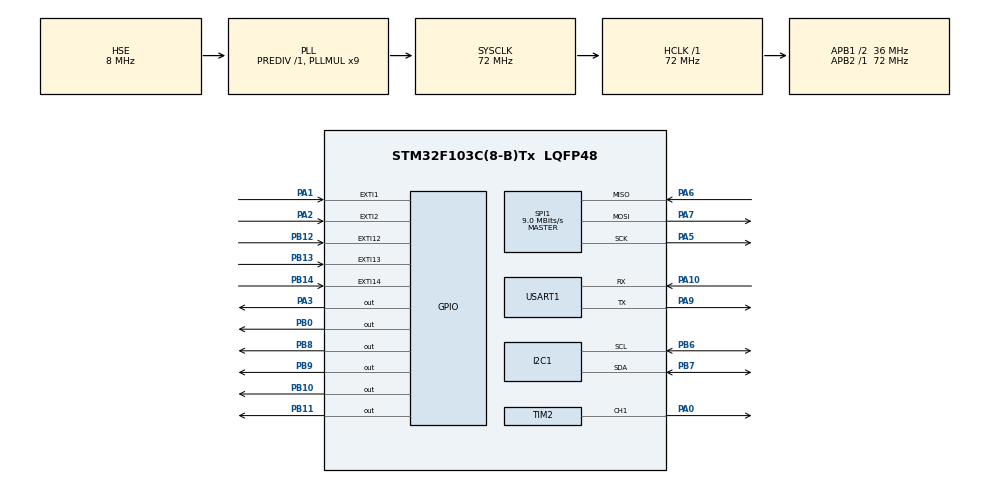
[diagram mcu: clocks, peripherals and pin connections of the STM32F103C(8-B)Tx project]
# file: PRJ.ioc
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I2C1.I2C_Mode=I2C_Standard
Mcu.Family=STM32F1
Mcu.Name=STM32F103C(8-B)Tx
Mcu.Package=LQFP48
NVIC.EXTI15_10_IRQn=true\:1\:0\:true\:false\:true\:true\:true\:true
NVIC.EXTI1_IRQn=true\:1\:0\:true\:false\:true\:true\:true\:true
NVIC.EXTI2_IRQn=true\:1\:0\:true\:false\:true\:true\:true\:true
NVIC.PriorityGroup=NVIC_PRIORITYGROUP_4
NVIC.TIM2_IRQn=true\:2\:0\:true\:false\:true\:true\:true\:true
NVIC.USART1_IRQn=true\:3\:0\:true\:false\:true\:true\:true\:true
PA0-WKUP.Signal=S_TIM2_CH1_ETR
PA1.GPIO_PuPd=GPIO_PULLUP
PA1.Signal=GPXTI1
PA10.Mode=Asynchronous
PA10.Signal=USART1_RX
PA13.Mode=Serial_Wire
PA13.Signal=SYS_JTMS-SWDIO
PA14.Mode=Serial_Wire
PA14.Signal=SYS_JTCK-SWCLK
PA2.GPIO_PuPd=GPIO_PULLUP
PA2.Signal=GPXTI2
PA3.Signal=GPIO_Output
PA5.Mode=Full_Duplex_Master
PA5.Signal=SPI1_SCK
PA6.Mode=Full_Duplex_Master
PA6.Signal=SPI1_MISO
PA7.Mode=Full_Duplex_Master
PA7.Signal=SPI1_MOSI
PA9.Mode=Asynchronous
PA9.Signal=USART1_TX
PB0.Signal=GPIO_Output
PB10.Signal=GPIO_Output
PB11.Signal=GPIO_Output
PB12.Signal=GPXTI12
PB13.GPIO_ModeDefaultEXTI=GPIO_MODE_IT_RISING
PB13.GPIO_PuPd=GPIO_PULLUP
PB13.Signal=GPXTI13
PB14.GPIO_ModeDefaultEXTI=GPIO_MODE_IT_RISING
PB14.GPIO_PuPd=GPIO_PULLUP
PB14.Signal=GPXTI14
PB6.Mode=I2C
PB6.Signal=I2C1_SCL
PB7.Mode=I2C
PB7.Signal=I2C1_SDA
PB8.Signal=GPIO_Output
PB9.Signal=GPIO_Output
PD0-OSC_IN.Mode=HSE-External-Oscillator
PD0-OSC_IN.Signal=RCC_OSC_IN
PD1-OSC_OUT.Mode=HSE-External-Oscillator
PD1-OSC_OUT.Signal=RCC_OSC_OUT
ProjectManager.HeapSize=0x200
ProjectManager.StackSize=0x400
ProjectManager.TargetToolchain=CMake
RCC.AHBFreq_Value=72000000
RCC.APB1CLKDivider=RCC_HCLK_DIV2
RCC.APB1Freq_Value=36000000
RCC.APB1TimFreq_Value=72000000
RCC.APB2Freq_Value=72000000
RCC.APB2TimFreq_Value=72000000
RCC.HCLKFreq_Value=72000000
RCC.PLLMUL=RCC_PLL_MUL9
RCC.PLLSourceVirtual=RCC_PLLSOURCE_HSE
RCC.SYSCLKFreq_VALUE=72000000
RCC.SYSCLKSource=RCC_SYSCLKSOURCE_PLLCLK
RCC.USBFreq_Value=72000000
SH.S_TIM2_CH1_ETR.0=TIM2_CH1,PWM Generation1 CH1
SPI1.BaudRatePrescaler=SPI_BAUDRATEPRESCALER_8
SPI1.CalculateBaudRate=9.0 MBits/s
SPI1.Direction=SPI_DIRECTION_2LINES
SPI1.Mode=SPI_MODE_MASTER
SPI1.VirtualType=VM_MASTER
TIM2.Channel-PWM\ Generation1\ CH1=TIM_CHANNEL_1
TIM2.Period=19999
TIM2.Prescaler=71
USART1.VirtualMode=VM_ASYNC
VP_TIM2_VS_ClockSourceINT.Mode=Internal
board=custom

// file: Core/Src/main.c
/* USER CODE BEGIN Header */
/**
  ******************************************************************************
  * @file           : main.c
  * @brief          : Main program body
  ******************************************************************************
  * @attention
  *
  * Copyright (c) 2026 STMicroelectronics.
  * All rights reserved.
  *
  * This software is licensed under terms that can be found in the LICENSE file
  * in the root directory of this software component.
  * If no LICENSE file comes with this software, it is provided AS-IS.
  *
  ******************************************************************************
  */
/* USER CODE END Header */
#include "main.h"

/* USER CODE BEGIN Includes */
#include "App.h"
/* USER CODE END Includes */

I2C_HandleTypeDef hi2c1;

SPI_HandleTypeDef hspi1;

TIM_HandleTypeDef htim2;

UART_HandleTypeDef huart1;

/* USER CODE BEGIN PV */
Servo_t servo = {&htim2, TIM_CHANNEL_1};
Buzzer_t buzzer = {GPIOA, GPIO_PIN_3};

Keypad_t keypad = {
    // Cot (Columns) - PB12, PB13, PB14: input pull-up, EXTI falling
    .Col1_Port = GPIOB, .Col2_Port = GPIOB, .Col3_Port = GPIOB,
    .Col1_Pin  = GPIO_PIN_12, .Col2_Pin = GPIO_PIN_13, .Col3_Pin = GPIO_PIN_14,
    .Col1_IRQn = EXTI15_10_IRQn, .Col2_IRQn = EXTI15_10_IRQn, .Col3_IRQn = EXTI15_10_IRQn,
    // Hang (Rows) - PB8, PB9, PB10, PB11: output push-pull
    .Row1_Port = GPIOB, .Row2_Port = GPIOB, .Row3_Port = GPIOB, .Row4_Port = GPIOB,
    .Row1_Pin  = GPIO_PIN_8, .Row2_Pin = GPIO_PIN_9, .Row3_Pin = GPIO_PIN_10, .Row4_Pin = GPIO_PIN_11,
};

/* USER CODE END PV */

void SystemClock_Config(void);
static void MX_GPIO_Init(void);
static void MX_I2C1_Init(void);
static void MX_SPI1_Init(void);
static void MX_TIM2_Init(void);
static void MX_USART1_UART_Init(void);

int main(void)
{

  /* MCU Configuration--------------------------------------------------------*/

  /* Reset of all peripherals, Initializes the Flash interface and the Systick. */
  HAL_Init();

  /* Configure the system clock */
  SystemClock_Config();

  /* Initialize all configured peripherals */
  MX_GPIO_Init();
  MX_I2C1_Init();
  MX_SPI1_Init();
  MX_TIM2_Init();
  MX_USART1_UART_Init();
  /* USER CODE BEGIN 2 */
  HAL_Delay(100);
  Flash_Load_Cards();
  App_Init(&keypad ,&buzzer, &huart1, &hi2c1, &hspi1, &servo);

  /* USER CODE END 2 */

  /* Infinite loop */
  /* USER CODE BEGIN WHILE */
  while (1)
  {
    App_Run();

    /* USER CODE END WHILE */

  }
}

void SystemClock_Config(void)
{
  RCC_OscInitTypeDef RCC_OscInitStruct = {0};
  RCC_ClkInitTypeDef RCC_ClkInitStruct = {0};

  /** Initializes the RCC Oscillators according to the specified parameters
  * in the RCC_OscInitTypeDef structure.
  */
  RCC_OscInitStruct.OscillatorType = RCC_OSCILLATORTYPE_HSE;
  RCC_OscInitStruct.HSEState = RCC_HSE_ON;
  RCC_OscInitStruct.HSEPredivValue = RCC_HSE_PREDIV_DIV1;
  RCC_OscInitStruct.HSIState = RCC_HSI_ON;
  RCC_OscInitStruct.PLL.PLLState = RCC_PLL_ON;
  RCC_OscInitStruct.PLL.PLLSource = RCC_PLLSOURCE_HSE;
  RCC_OscInitStruct.PLL.PLLMUL = RCC_PLL_MUL9;
  if (HAL_RCC_OscConfig(&RCC_OscInitStruct) != HAL_OK)
  {
    Error_Handler();
  }

  /** Initializes the CPU, AHB and APB buses clocks
  */
  RCC_ClkInitStruct.ClockType = RCC_CLOCKTYPE_HCLK|RCC_CLOCKTYPE_SYSCLK
                              |RCC_CLOCKTYPE_PCLK1|RCC_CLOCKTYPE_PCLK2;
  RCC_ClkInitStruct.SYSCLKSource = RCC_SYSCLKSOURCE_PLLCLK;
  RCC_ClkInitStruct.AHBCLKDivider = RCC_SYSCLK_DIV1;
  RCC_ClkInitStruct.APB1CLKDivider = RCC_HCLK_DIV2;
  RCC_ClkInitStruct.APB2CLKDivider = RCC_HCLK_DIV1;

  if (HAL_RCC_ClockConfig(&RCC_ClkInitStruct, FLASH_LATENCY_2) != HAL_OK)
  {
    Error_Handler();
  }
}

static void MX_I2C1_Init(void)
{

  hi2c1.Instance = I2C1;
  hi2c1.Init.ClockSpeed = 100000;
  hi2c1.Init.DutyCycle = I2C_DUTYCYCLE_2;
  hi2c1.Init.OwnAddress1 = 0;
  hi2c1.Init.AddressingMode = I2C_ADDRESSINGMODE_7BIT;
  hi2c1.Init.DualAddressMode = I2C_DUALADDRESS_DISABLE;
  hi2c1.Init.OwnAddress2 = 0;
  hi2c1.Init.GeneralCallMode = I2C_GENERALCALL_DISABLE;
  hi2c1.Init.NoStretchMode = I2C_NOSTRETCH_DISABLE;
  if (HAL_I2C_Init(&hi2c1) != HAL_OK)
  {
    Error_Handler();
  }

}

static void MX_SPI1_Init(void)
{

  /* SPI1 parameter configuration*/
  hspi1.Instance = SPI1;
  hspi1.Init.Mode = SPI_MODE_MASTER;
  hspi1.Init.Direction = SPI_DIRECTION_2LINES;
  hspi1.Init.DataSize = SPI_DATASIZE_8BIT;
  hspi1.Init.CLKPolarity = SPI_POLARITY_LOW;
  hspi1.Init.CLKPhase = SPI_PHASE_1EDGE;
  hspi1.Init.NSS = SPI_NSS_SOFT;
  hspi1.Init.BaudRatePrescaler = SPI_BAUDRATEPRESCALER_8;
  hspi1.Init.FirstBit = SPI_FIRSTBIT_MSB;
  hspi1.Init.TIMode = SPI_TIMODE_DISABLE;
  hspi1.Init.CRCCalculation = SPI_CRCCALCULATION_DISABLE;
  hspi1.Init.CRCPolynomial = 10;
  if (HAL_SPI_Init(&hspi1) != HAL_OK)
  {
    Error_Handler();
  }

}

static void MX_TIM2_Init(void)
{

  TIM_ClockConfigTypeDef sClockSourceConfig = {0};
  TIM_MasterConfigTypeDef sMasterConfig = {0};
  TIM_OC_InitTypeDef sConfigOC = {0};

  htim2.Instance = TIM2;
  htim2.Init.Prescaler = 71;
  htim2.Init.CounterMode = TIM_COUNTERMODE_UP;
  htim2.Init.Period = 19999;
  htim2.Init.ClockDivision = TIM_CLOCKDIVISION_DIV1;
  htim2.Init.AutoReloadPreload = TIM_AUTORELOAD_PRELOAD_DISABLE;
  if (HAL_TIM_Base_Init(&htim2) != HAL_OK)
  {
    Error_Handler();
  }
  sClockSourceConfig.ClockSource = TIM_CLOCKSOURCE_INTERNAL;
  if (HAL_TIM_ConfigClockSource(&htim2, &sClockSourceConfig) != HAL_OK)
  {
    Error_Handler();
  }
  if (HAL_TIM_PWM_Init(&htim2) != HAL_OK)
  {
    Error_Handler();
  }
  sMasterConfig.MasterOutputTrigger = TIM_TRGO_RESET;
  sMasterConfig.MasterSlaveMode = TIM_MASTERSLAVEMODE_DISABLE;
  if (HAL_TIMEx_MasterConfigSynchronization(&htim2, &sMasterConfig) != HAL_OK)
  {
    Error_Handler();
  }
  sConfigOC.OCMode = TIM_OCMODE_PWM1;
  sConfigOC.Pulse = 0;
  sConfigOC.OCPolarity = TIM_OCPOLARITY_HIGH;
  sConfigOC.OCFastMode = TIM_OCFAST_DISABLE;
  if (HAL_TIM_PWM_ConfigChannel(&htim2, &sConfigOC, TIM_CHANNEL_1) != HAL_OK)
  {
    Error_Handler();
  }
  HAL_TIM_MspPostInit(&htim2);

}

static void MX_USART1_UART_Init(void)
{

  huart1.Instance = USART1;
  huart1.Init.BaudRate = 115200;
  huart1.Init.WordLength = UART_WORDLENGTH_8B;
  huart1.Init.StopBits = UART_STOPBITS_1;
  huart1.Init.Parity = UART_PARITY_NONE;
  huart1.Init.Mode = UART_MODE_TX_RX;
  huart1.Init.HwFlowCtl = UART_HWCONTROL_NONE;
  huart1.Init.OverSampling = UART_OVERSAMPLING_16;
  if (HAL_UART_Init(&huart1) != HAL_OK)
  {
    Error_Handler();
  }

}

static void MX_GPIO_Init(void)
{
  GPIO_InitTypeDef GPIO_InitStruct = {0};

  /* GPIO Ports Clock Enable */
  __HAL_RCC_GPIOD_CLK_ENABLE();
  __HAL_RCC_GPIOA_CLK_ENABLE();
  __HAL_RCC_GPIOB_CLK_ENABLE();

  /*Configure GPIO pin Output Level */
  HAL_GPIO_WritePin(GPIOA, GPIO_PIN_3, GPIO_PIN_RESET);

  /*Configure GPIO pin Output Level */
  HAL_GPIO_WritePin(GPIOB, GPIO_PIN_0|GPIO_PIN_10|GPIO_PIN_11|GPIO_PIN_8
                          |GPIO_PIN_9, GPIO_PIN_RESET);

  /*Configure GPIO pins : PA1 PA2 */
  GPIO_InitStruct.Pin = GPIO_PIN_1|GPIO_PIN_2;
  GPIO_InitStruct.Mode = GPIO_MODE_IT_RISING;
  GPIO_InitStruct.Pull = GPIO_PULLUP;
  HAL_GPIO_Init(GPIOA, &GPIO_InitStruct);

  /*Configure GPIO pin : PA3 */
  GPIO_InitStruct.Pin = GPIO_PIN_3;
  GPIO_InitStruct.Mode = GPIO_MODE_OUTPUT_PP;
  GPIO_InitStruct.Pull = GPIO_NOPULL;
  GPIO_InitStruct.Speed = GPIO_SPEED_FREQ_LOW;
  HAL_GPIO_Init(GPIOA, &GPIO_InitStruct);

  /*Configure GPIO pins : PB0 PB10 PB11 PB8
                           PB9 */
  GPIO_InitStruct.Pin = GPIO_PIN_0|GPIO_PIN_10|GPIO_PIN_11|GPIO_PIN_8
                          |GPIO_PIN_9;
  GPIO_InitStruct.Mode = GPIO_MODE_OUTPUT_PP;
  GPIO_InitStruct.Pull = GPIO_NOPULL;
  GPIO_InitStruct.Speed = GPIO_SPEED_FREQ_LOW;
  HAL_GPIO_Init(GPIOB, &GPIO_InitStruct);

  /*Configure GPIO pins : PB12 PB13 PB14 */
  GPIO_InitStruct.Pin = GPIO_PIN_12|GPIO_PIN_13|GPIO_PIN_14;
  GPIO_InitStruct.Mode = GPIO_MODE_IT_FALLING;

  GPIO_InitStruct.Pull = GPIO_PULLUP;
  HAL_GPIO_Init(GPIOB, &GPIO_InitStruct);

  /* EXTI interrupt init*/
  HAL_NVIC_SetPriority(EXTI1_IRQn, 1, 0);
  HAL_NVIC_EnableIRQ(EXTI1_IRQn);

  HAL_NVIC_SetPriority(EXTI2_IRQn, 1, 0);
  HAL_NVIC_EnableIRQ(EXTI2_IRQn);

  HAL_NVIC_SetPriority(EXTI15_10_IRQn, 1, 0);
  HAL_NVIC_EnableIRQ(EXTI15_10_IRQn);

}

void Error_Handler(void)
{
  __disable_irq();
  while (1)
  {
  }
}
